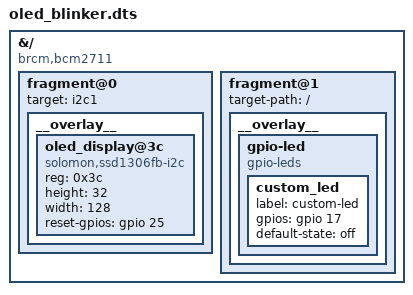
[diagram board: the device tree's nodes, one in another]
/dts-v1/;
/plugin/;

&{/} {
    compatible = "brcm,bcm2711";

    fragment@0 {
        target = <&i2c1>;
        __overlay__ {
            #address-cells = <1>;
            #size-cells = <0>;
            status = "okay";

            oled_display@3c {
                compatible = "solomon,ssd1306fb-i2c";
                reg = <0x3c>;
                height = <32>;
                width = <128>;
                reset-gpios = <&gpio 25 0>; // Optional
            };
        };
    };

    fragment@1 {
        target-path = "/";
        __overlay__ {
            gpio-led {
                compatible = "gpio-leds";
                custom_led {
                    label = "custom-led";
                    gpios = <&gpio 17 0>;
                    default-state = "off";
                };
            };
        };
    };
};

